AUTOSAR XML (schema 314)
package /ComponentType
  internal behavior Sa_MtrPos2_InternalBehavior: component=Sa_MtrPos2
    timing event MtrPos2_Init1_InitEvent: start-on-event=MtrPos2_Init1, period=0
    timing event TMT_MtrPos2_Per1: start-on-event=MtrPos2_Per1, period=0.002
    port-api-options:
      enable-take-address=false, indirect-api=false, port=CorrectedMtrPos
      enable-take-address=false, indirect-api=false, port=CosTheta1
      enable-take-address=false, indirect-api=false, port=MechMtrPos
      enable-take-address=false, indirect-api=false, port=MotorVelMRF
      enable-take-address=false, indirect-api=false, port=NxtrDiagMgr
      enable-take-address=false, indirect-api=false, port=SinTheta1
      enable-take-address=false, indirect-api=false, port=SysCCorrectedMtrPos
      enable-take-address=false, indirect-api=false, port=SysCMechMtrPos
    runnable MtrPos2_Init1
    runnable MtrPos2_Per1
      data read access READ_MotorVelMRF_MtrRadpS_f32: data-element=MotorVelMRF.MtrRadpS_f32
      6 x data write access:
        WRITE_CorrectedMtrPos_Rev_f32: data-element=CorrectedMtrPos.Rev_f32
        WRITE_CosTheta1_Volt_f32: data-element=CosTheta1.Volt_f32
        WRITE_MechMtrPos_Rev_f32: data-element=MechMtrPos.Rev_f32
        WRITE_SinTheta1_Volt_f32: data-element=SinTheta1.Volt_f32
        WRITE_SysCCorrectedMtrPos_Rev_f32: data-element=SysCCorrectedMtrPos.Rev_f32
        WRITE_SysCMechMtrPos_Rev_f32: data-element=SysCMechMtrPos.Rev_f32
      sync call SC_NxtrDiagMgr_GetNTCFailed: operation=NxtrDiagMgr.GetNTCFailed, timeout=0
      sync call SC_NxtrDiagMgr_SetNTCStatus: operation=NxtrDiagMgr.SetNTCStatus, timeout=0
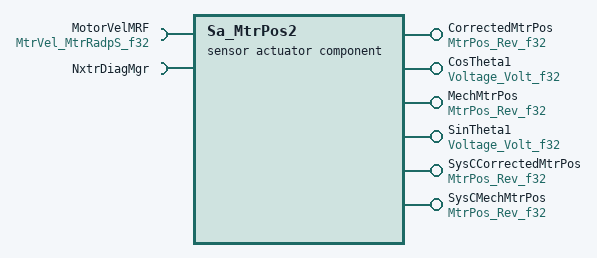
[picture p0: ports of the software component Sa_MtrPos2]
  sensor actuator software component type Sa_MtrPos2
    6 x provide port:
      CorrectedMtrPos: unqueued-sender-com-spec{data-element=Rev_f32, can-invalidate=false, init-value=D_ZERO_ULS_F32}, provided-interface=MtrPos_Rev_f32
      CosTheta1: unqueued-sender-com-spec{data-element=Volt_f32, can-invalidate=false, init-value=D_ZERO_ULS_F32}, provided-interface=Voltage_Volt_f32
      MechMtrPos: unqueued-sender-com-spec{data-element=Rev_f32, can-invalidate=false, init-value=D_ZERO_ULS_F32}, provided-interface=MtrPos_Rev_f32
      SinTheta1: unqueued-sender-com-spec{data-element=Volt_f32, can-invalidate=false, init-value=D_ZERO_ULS_F32}, provided-interface=Voltage_Volt_f32
      SysCCorrectedMtrPos: unqueued-sender-com-spec{data-element=Rev_f32, can-invalidate=false, init-value=D_ZERO_ULS_F32}, provided-interface=MtrPos_Rev_f32
      SysCMechMtrPos: unqueued-sender-com-spec{data-element=Rev_f32, can-invalidate=false, init-value=D_ZERO_ULS_F32}, provided-interface=MtrPos_Rev_f32
    require port MotorVelMRF: unqueued-receiver-com-spec{data-element=MtrRadpS_f32, init-value=D_ZERO_ULS_F32}, required-interface=MtrVel_MtrRadpS_f32
    require port NxtrDiagMgr: required-com-specs=[GetNTCActive, GetNTCFailed, GetNTCStatus, SetNTCStatus], required-interface=NxtrDiagMgr
  swc implementation Sa_MtrPos2_Implementation: behavior=Sa_MtrPos2_InternalBehavior
    code-descriptors:
      code Code: type=SRC
